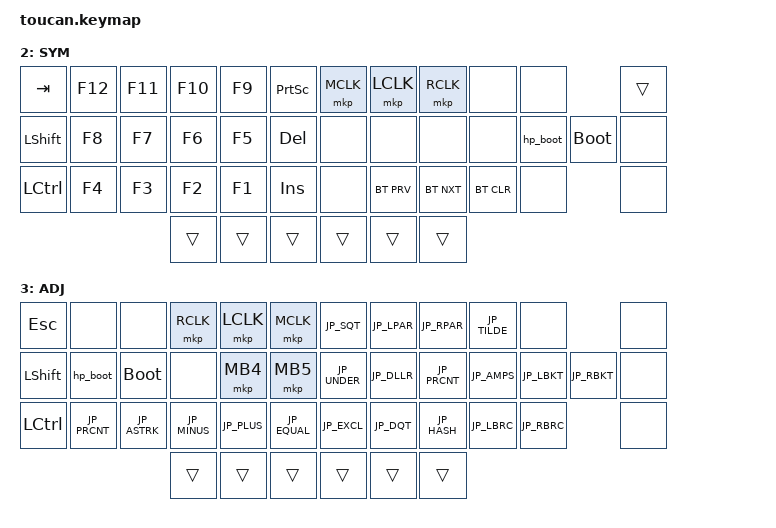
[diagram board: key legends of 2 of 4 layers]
#define ZMK_POINTING_DEFAULT_SCRL_VAL 20    // default: 10

#include <behaviors.dtsi>
#include <dt-bindings/zmk/keys.h>
#include <dt-bindings/zmk/bt.h>
#include <dt-bindings/zmk/outputs.h>
#include <dt-bindings/zmk/pointing.h>

/* JIS Key Aliases */
#define JP_ZKHK  GRAVE
#define JP_MINUS MINUS
#define JP_CARET EQUAL
#define JP_YEN   INT3
#define JP_AT    LBKT
#define JP_LBKT  RBKT
#define JP_EISU  CAPS
#define JP_SEMI  SEMI
#define JP_COLON SQT
#define JP_RBKT  NUHS
#define JP_COMMA COMMA
#define JP_DOT   DOT
#define JP_SLASH SLASH
#define JP_BSLH  INT1
#define JP_MHEN  INT5
#define JP_HENK  INT4
#define JP_KANA  INT2
#define JP_EXCL  LS(N1)
#define JP_DQT   LS(N2)
#define JP_HASH  LS(N3)
#define JP_DLLR  LS(N4)
#define JP_PRCNT LS(N5)
#define JP_AMPS  LS(N6)
#define JP_SQT   LS(N7)
#define JP_LPAR  LS(N8)
#define JP_RPAR  LS(N9)
#define JP_EQUAL LS(JP_MINUS)
#define JP_TILDE LS(JP_CARET)
#define JP_PIPE  LS(JP_YEN)
#define JP_GRAVE LS(JP_AT)
#define JP_LBRC  LS(JP_LBKT)
#define JP_CAPS  LS(JP_EISU)
#define JP_PLUS  LS(JP_SEMI)
#define JP_ASTRK LS(JP_COLON)
#define JP_RBRC  LS(JP_RBKT)
#define JP_LT    LS(JP_COMMA)
#define JP_RT    LS(JP_DOT)
#define JP_QMARK LS(JP_SLASH)
#define JP_UNDER LS(JP_BSLH)

#define BASE 0
#define NAV  1
#define SYM  2
#define ADJ  3

/ {
    behaviors {
        // 長押しでブートローダー、タップで元のキー（ここでは例として F12）
        hp_boot: hp_boot {
            compatible = "zmk,behavior-hold-tap";
            #binding-cells = <2>;
            flavor = "hold-preferred";
            tapping-term-ms = <3000>; // 2秒間長押しで発動（誤爆防止のため長めが推奨）
            bindings = <&bootloader>, <&kp>;
        };
    };

    macros {
        // スクロールアップ (ズームイン相当): Ctrl + ホイール上
        zm_in: zm_in {
            compatible = "zmk,behavior-macro";
            #binding-cells = <0>;
            wait-ms = <30>;  // 少しだけ動作を遅らせて確実に認識させる
            tap-ms = <30>;
            bindings
                = <&macro_press &kp LCTRL>
                , <&macro_wait_time 100>
                , <&macro_tap &msc SCRL_UP>
                , <&macro_release &kp LCTRL>
                ;
        };

        // スクロールダウン (ズームアウト相当): Ctrl + ホイール下
        zm_out: zm_out {
            compatible = "zmk,behavior-macro";
            #binding-cells = <0>;
            wait-ms = <30>;  // 少しだけ動作を遅らせて確実に認識させる
            tap-ms = <30>;
            bindings
                = <&macro_press &kp LCTRL>
                , <&macro_tap &msc SCRL_DOWN>
                , <&macro_release &kp LCTRL>
                ;
        };
    };

    keymap {
        compatible = "zmk,keymap";

        base_layer: base {
            display-name = "BASE";
            bindings = <
                &kp JP_ZKHK &kp Q &kp W &kp E &kp R &kp T   &kp Y &kp U  &kp I      &kp O   &kp P    &lt SYM JP_AT
                &kp LSHFT   &kp A &kp S &kp D &kp F &kp G   &kp H &kp J  &kp K      &kp L   &kp SEMI &kp JP_COLON
                &kp LCTRL   &kp Z &kp X &kp C &kp V &kp B   &kp N &kp M  &kp COMMA  &kp DOT &kp FSLH &kp JP_YEN
                                &kp LGUI &lt ADJ SPACE &kp TAB   &lt NAV BSPC &lt NAV RET &kp LALT
            >;
        };

        nav_layer: nav {
            display-name = "NAV";
            bindings = <
                &kp TAB    &none  &kp LEFT &kp UP   &kp RIGHT &msc SCRL_UP         &kp N7 &kp N8   &kp N9 &kp JP_MINUS &none &none
                &kp LSHFT  &none  &kp LEFT &kp DOWN &kp RIGHT &msc SCRL_DOWN       &kp N4 &kp N5   &kp N6 &kp N0       &none &none
                &kp LCTRL  &none  &none    &none    &none     &zm_in                &kp N1 &kp N2   &kp N3 &none        &none &none
                                                &trans     &trans       &trans      &trans  &trans   &trans
            >;
        };

        sym_layer: sym {
            display-name = "SYM";
            bindings = <
                &kp TAB   &kp F12  &kp F11 &kp F10  &kp F9  &kp PSCRN   &mkp MCLK &mkp LCLK  &mkp RCLK  &none      &none                  &trans
                &kp LSHFT &kp F8   &kp F7  &kp F6   &kp F5  &kp DEL     &none     &none      &none      &none      &hp_boot &bootloader 0 &none
                &kp LCTRL &kp F4   &kp F3  &kp F2   &kp F1  &kp INS     &none     &bt BT_PRV &bt BT_NXT &bt BT_CLR &none                  &none
                                          &trans    &trans   &trans   &trans   &trans    &trans
            >;
        };

        adj_layer: adj {
            display-name = "ADJ";
            bindings = <
                &kp ESC   &none                   &none        &mkp RCLK    &mkp LCLK    &mkp MCLK       &kp JP_SQT  &kp JP_LPAR     &kp JP_RPAR &kp JP_TILDE &none       &none
                &kp LSHFT &hp_boot &bootloader 0  &none        &mkp MB4     &mkp MB5     &kp JP_UNDER     &kp JP_DLLR &kp JP_PRCNT    &kp JP_AMPS &kp JP_LBKT  &kp JP_RBKT &none
                &kp LCTRL &kp JP_PRCNT            &kp JP_ASTRK &kp JP_MINUS &kp JP_PLUS  &kp JP_EQUAL    &kp JP_EXCL &kp JP_DQT      &kp JP_HASH &kp JP_LBRC  &kp JP_RBRC &none
                                          &trans  &trans   &trans   &trans   &trans    &trans
            >;
        };
    };
};
